# TEST_MCUTEST register map
Vendor: TestVendor; File version: 1.0
Minimal test device for SVD parser testing
CPU: CM4 r0p0, little endian, MPU, FPU, 4 interrupt priority bits
Registers are 32-bit, read-write, reset 0x0 unless marked. A register's access mark holds for its fields unless they carry their own. Offsets are from the block's base; lines under a group give offsets from that group; [hi:lo] are bit positions; {n}, {i} and the like mark numbered series; 'fields as' and 'values as' point back to an identical list; <NAME> marks a mode.

## Memory map
0x40000000 TIM2 — General-purpose timer 2
0x40020000 GPIOA — General Purpose I/O Port A

## Interrupts
10 GPIOA_IRQn (GPIOA) — GPIO Port A interrupt
28 TIM2_IRQn (TIM2) — Timer 2 global interrupt

## GPIOA — General Purpose I/O Port A
Base 0x40020000
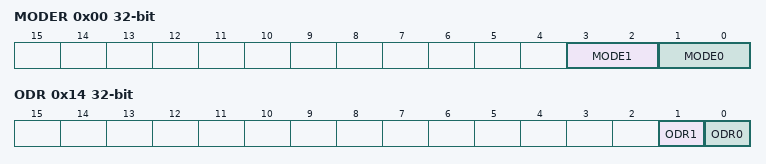
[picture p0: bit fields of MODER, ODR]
0x00 MODER — GPIO port mode register
  [3:2] MODE1 — Port x configuration bits (y = 0..15)
  [1:0] MODE0 — Port x configuration bits (y = 0..15)
    0=Input mode; 1=Output mode; 2=Alternate function mode; 3=Analog mode
0x04 OTYPER — GPIO port output type register
  [0] OT0 — Port x configuration bits (y = 0..15)
    0=PushPull (Output push-pull); 1=OpenDrain (Output open-drain)
0x14 ODR — GPIO port output data register
  [1] ODR1 — Port output data (y = 0..15)
  [0] ODR0 — Port output data (y = 0..15)

## TIM2 — General-purpose timer 2
Base 0x40000000
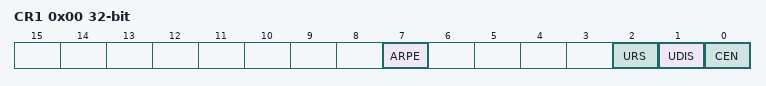
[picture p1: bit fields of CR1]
0x00 CR1 — Control register 1
  [7] ARPE — Auto-reload preload enable
  [2] URS — Update request source
  [1] UDIS — Update disable
  [0] CEN — Counter enable
    0=Disabled (Counter disabled); 1=Enabled (Counter enabled)
0x10 SR — Status register
  [0] UIF — Update interrupt flag
0x2C ARR — Auto-reload register
  [15:0] ARR — Auto-reload value
